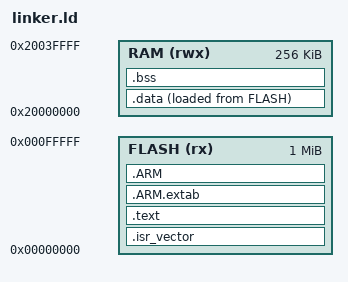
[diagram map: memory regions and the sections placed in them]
/* nRF52840: 1 MB FLASH, 256 KB RAM (matches examples/bare-metal/nrf52840-dk/memory.x). */

ENTRY(Reset_Handler)

MEMORY
{
    FLASH (rx)  : ORIGIN = 0x00000000, LENGTH = 1024K
    RAM   (rwx) : ORIGIN = 0x20000000, LENGTH = 256K
}

_estack = ORIGIN(RAM) + LENGTH(RAM);

SECTIONS
{
    .isr_vector :
    {
        . = ALIGN(4);
        KEEP(*(.isr_vector))
        . = ALIGN(4);
    } > FLASH

    .text :
    {
        . = ALIGN(4);
        *(.text)
        *(.text*)
        *(.rodata)
        *(.rodata*)
        . = ALIGN(4);
    } > FLASH

    .ARM.extab : { *(.ARM.extab*) } > FLASH
    .ARM : { *(.ARM.exidx*) } > FLASH

    _sidata = LOADADDR(.data);

    .data :
    {
        . = ALIGN(4);
        _sdata = .;
        *(.data)
        *(.data*)
        . = ALIGN(4);
        _edata = .;
    } > RAM AT > FLASH

    .bss :
    {
        . = ALIGN(4);
        _sbss = .;
        *(.bss)
        *(.bss*)
        *(COMMON)
        . = ALIGN(4);
        _ebss = .;
    } > RAM

    /* heap_4.c carves the FreeRTOS heap out of the configTOTAL_HEAP_SIZE array in
     * .bss, so no separate heap region is needed here. */
}
